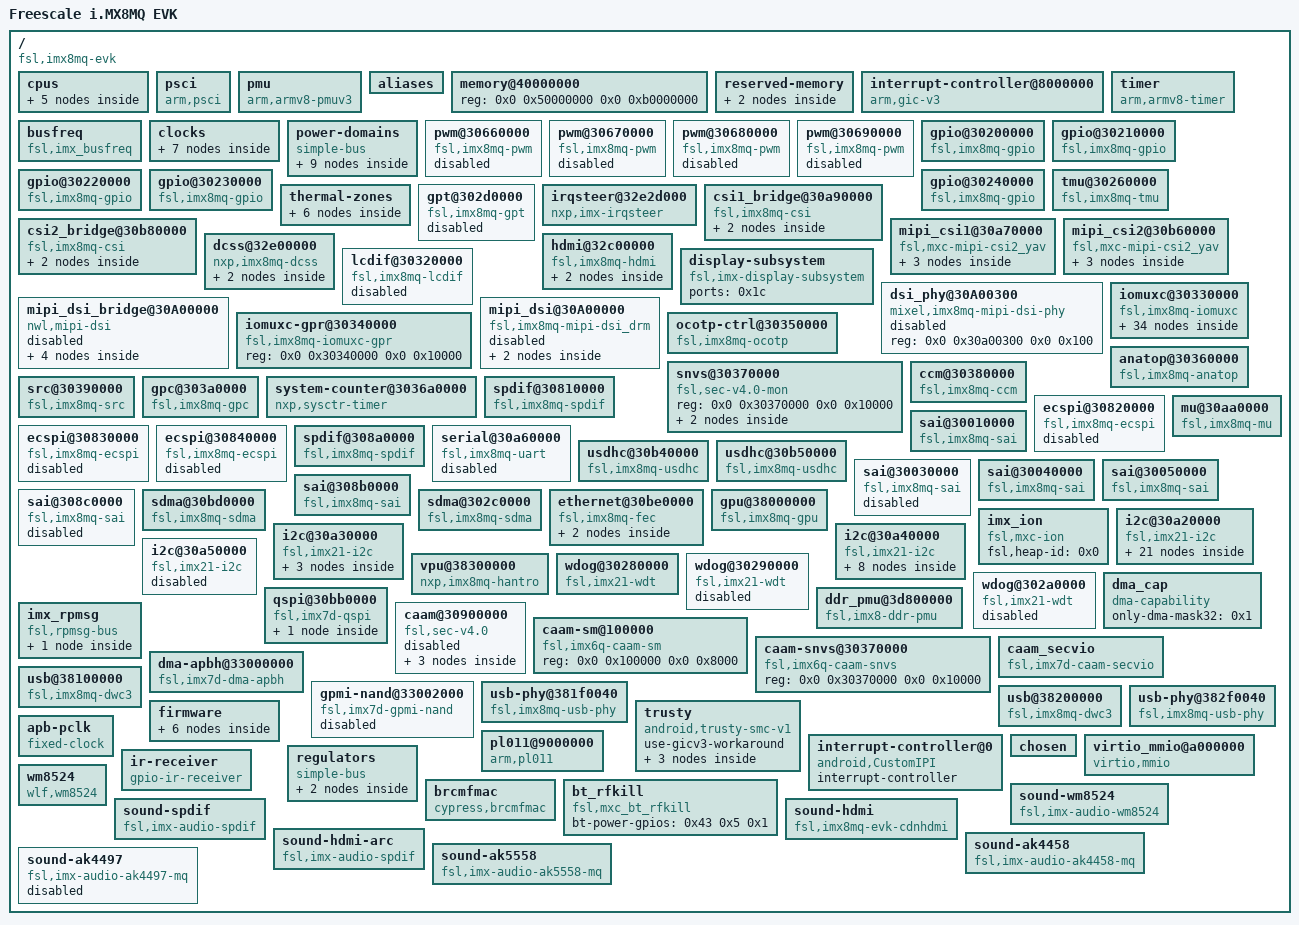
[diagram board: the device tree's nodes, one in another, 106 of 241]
/dts-v1/;

/ {
	compatible = "fsl,imx8mq-evk", "fsl,imx8mq";
	interrupt-parent = <0x1>;
	#address-cells = <0x2>;
	#size-cells = <0x2>;
	model = "Freescale i.MX8MQ EVK";

	cpus {
		#address-cells = <0x2>;
		#size-cells = <0x0>;

		idle-states {
			entry-method = "psci";

			cpu-sleep {
				compatible = "arm,idle-state";
				arm,psci-suspend-param = <0x10033>;
				entry-latency-us = <0x3e8>;
				exit-latency-us = <0x2bc>;
				min-residency-us = <0xa8c>;
				local-timer-stop;
				wakeup-latency-us = <0x5dc>;
				phandle = <0x3>;
			};

			cluster-sleep {
				compatible = "arm,idle-state";
				arm,psci-suspend-param = <0x1000000>;
				entry-latency-us = <0x3e8>;
				exit-latency-us = <0x2bc>;
				min-residency-us = <0xa8c>;
				wakeup-latency-us = <0x5dc>;
			};
		};

		cpu@0 {
			device_type = "cpu";
			compatible = "arm,cortex-a53";
			reg = <0x0 0x0>;
			enable-method = "psci";
			next-level-cache = <0x2>;
			cpu-idle-states = <0x3>;
			operating-points = <0x16e360 0xf4240 0x13d620 0xf4240 0xf4240 0xdbba0 0xc3500 0xdbba0>;
			clocks = <0x4 0x5a 0x4 0x58 0x4 0xa 0x4 0xc 0x4 0x4e>;
			clock-names = "a53", "arm_a53_src", "arm_pll", "arm_pll_out", "sys1_pll_800m";
			clock-latency = <0xee6c>;
			#cooling-cells = <0x2>;
			dc-supply = <0x5>;
			phandle = <0x6>;
		};
/*
		cpu@1 {
			device_type = "cpu";
			compatible = "arm,cortex-a53";
			reg = <0x0 0x1>;
			enable-method = "psci";
			next-level-cache = <0x2>;
			cpu-idle-states = <0x3>;
			phandle = <0x7>;
		};

		cpu@2 {
			device_type = "cpu";
			compatible = "arm,cortex-a53";
			reg = <0x0 0x2>;
			enable-method = "psci";
			next-level-cache = <0x2>;
			cpu-idle-states = <0x3>;
			phandle = <0x8>;
		};

		cpu@3 {
			device_type = "cpu";
			compatible = "arm,cortex-a53";
			reg = <0x0 0x3>;
			enable-method = "psci";
			next-level-cache = <0x2>;
			cpu-idle-states = <0x3>;
			phandle = <0x9>;
		};
*/
		l2-cache0 {
			compatible = "cache";
			phandle = <0x2>;
		};
	};

	psci {
		compatible = "arm,psci";
		method = "hvc";
		cpu_suspend = <0xc4000001>;
		cpu_off = <0xc4000002>;
		cpu_on = <0xc4000003>;
	};

	pmu {
		compatible = "arm,armv8-pmuv3";
		interrupts = <0x1 0x7 0x3f04>;
		interrupt-affinity = <0x6 0x7 0x8 0x9>;
		interrupt-parent = <0xa>;
	};

	aliases {
		csi0 = "/mipi_csi1@30a70000";
		csi1 = "/mipi_csi2@30b60000";
		ethernet0 = "/ethernet@30be0000";
		serial0 = "/serial@30860000";
		serial1 = "/serial@30890000";
		serial2 = "/serial@30880000";
		serial3 = "/serial@30a60000";
		spi0 = "/ecspi@30820000";
		spi1 = "/ecspi@30830000";
		spi2 = "/ecspi@30840000";
		mmc0 = "/usdhc@30b40000";
		mmc1 = "/usdhc@30b50000";
		gpio0 = "/gpio@30200000";
		gpio1 = "/gpio@30210000";
		gpio2 = "/gpio@30220000";
		gpio3 = "/gpio@30230000";
		gpio4 = "/gpio@30240000";
		dsi_phy0 = "/dsi_phy@30A00300";
		mipi_dsi0 = "/mipi_dsi@30A00000";
	};

	memory@40000000 {
		device_type = "memory";
		reg = <0x0 0x50000000 0x0 0xb0000000>;
	};

	reserved-memory {
		#address-cells = <0x2>;
		#size-cells = <0x2>;
		ranges;

		rpmsg@b8000000 {
			no-map;
			reg = <0x0 0xb8000000 0x0 0x400000>;
			phandle = <0x52>;
		};

		imx_ion@0 {
			compatible = "imx-ion-pool";
			/* reg = <0x0 0xf6000000 0x0 0x8000000>; */
			reg = <0x0 0x96400000 0x0 0x2000000>;
		};
	};

	interrupt-controller@8000000 {
		compatible = "arm,gic-v3";
		phandle = <0xa>;
		interrupts = <0x1 0x9 0x4>;
		interrupt-parent = <0xa>;
		reg = <0x00 0x8000000 0x00 0x10000 0x00 0x80a0000 0x00 0xf60000>;
		ranges;
		#address-cells = <0x02>;
		#redistributor-regions = <0x01>;
		interrupt-controller;
		#interrupt-cells = <0x03>;
		#size-cells = <0x02>;
	};

	timer {
		interrupts = <0x01 0x0d 0x04 0x01 0x0e 0x04 0x01 0x0b 0x04 0x01 0x0a 0x04>;
		compatible = "arm,armv8-timer\0arm,armv7-timer";
		always-on;
		interrupt-parent = <0xa>;
	};

	busfreq {
		compatible = "fsl,imx_busfreq";
		clocks = <0x4 0xf8 0x4 0x75 0x4 0x76 0x4 0x76 0x4 0x112 0x4 0x111 0x4 0x46 0x4 0x4d 0x4 0x48 0x4 0x4e 0x4 0x71 0x4 0x67 0x4 0x73 0x4 0x2 0x4 0x55 0x4 0x49>;
		clock-names = "dram_pll", "dram_alt_src", "dram_apb_src", "dram_apb_pre_div", "dram_core", "dram_alt_root", "sys1_pll_40m", "sys1_pll_400m", "sys1_pll_100m", "sys1_pll_800m", "noc_div", "main_axi_src", "ahb_div", "osc_25m", "sys2_pll_333m", "sys1_pll_133m";
		interrupts = <0x0 0x66 0x4 0x0 0x6d 0x4 0x0 0x6e 0x4 0x0 0x6f 0x4>;
		interrupt-name = "irq_busfreq_0", "irq_busfreq_1", "irq_busfreq_2", "irq_busfreq_3";
	};

	clocks {
		#address-cells = <0x1>;
		#size-cells = <0x0>;

		clock@0 {
			compatible = "fixed-clock";
			reg = <0x0>;
			#clock-cells = <0x0>;
			clock-frequency = <0x8000>;
			clock-output-names = "ckil";
			phandle = <0x24>;
		};

		clock@1 {
			compatible = "fixed-clock";
			reg = <0x1>;
			#clock-cells = <0x0>;
			clock-frequency = <0x17d7840>;
			clock-output-names = "osc_25m";
			phandle = <0x25>;
		};

		clock@2 {
			compatible = "fixed-clock";
			reg = <0x2>;
			#clock-cells = <0x0>;
			clock-frequency = <0x19bfcc0>;
			clock-output-names = "osc_27m";
			phandle = <0x26>;
		};

		clock@3 {
			compatible = "fixed-clock";
			reg = <0x3>;
			#clock-cells = <0x0>;
			clock-frequency = <0x7ed6b40>;
			clock-output-names = "clk_ext1";
			phandle = <0x27>;
		};

		clock@4 {
			compatible = "fixed-clock";
			reg = <0x4>;
			#clock-cells = <0x0>;
			clock-frequency = <0x7ed6b40>;
			clock-output-names = "clk_ext2";
			phandle = <0x28>;
		};

		clock@5 {
			compatible = "fixed-clock";
			reg = <0x5>;
			#clock-cells = <0x0>;
			clock-frequency = <0x7ed6b40>;
			clock-output-names = "clk_ext3";
			phandle = <0x29>;
		};

		clock@6 {
			compatible = "fixed-clock";
			reg = <0x6>;
			#clock-cells = <0x0>;
			clock-frequency = <0x7ed6b40>;
			clock-output-names = "clk_ext4";
			phandle = <0x2a>;
		};
	};

	power-domains {
		compatible = "simple-bus";
		#address-cells = <0x1>;
		#size-cells = <0x0>;

		power-domain@0 {
			compatible = "fsl,imx8mq-pm-domain";
			reg = <0x0>;
			#power-domain-cells = <0x0>;
			domain-name = "MIPI_PD";
			phandle = <0x20>;
		};

		power-domain@1 {
			compatible = "fsl,imx8mq-pm-domain";
			reg = <0x1>;
			#power-domain-cells = <0x0>;
			domain-name = "PCIE0_PD";
			phandle = <0x53>;
		};

		power-domain@2 {
			compatible = "fsl,imx8mq-pm-domain";
			reg = <0x2>;
			#power-domain-cells = <0x0>;
			domain-name = "USB_OTG1_PD";
			phandle = <0x59>;
		};

		power-domain@3 {
			compatible = "fsl,imx8mq-pm-domain";
			reg = <0x3>;
			#power-domain-cells = <0x0>;
			domain-name = "USB_OTG2_PD";
			phandle = <0x5c>;
		};

		power-domain@4 {
			compatible = "fsl,imx8mq-pm-domain";
			reg = <0x4>;
			#power-domain-cells = <0x0>;
			domain-name = "GPU_PD";
			clocks = <0x4 0x6f 0x4 0x66 0x4 0xe5 0x4 0x70>;
			power-supply = <0xb>;
			phandle = <0x40>;
		};

		power-domain@5 {
			compatible = "fsl,imx8mq-pm-domain";
			reg = <0x5>;
			#power-domain-cells = <0x0>;
			domain-name = "VPU_PD";
			clocks = <0x4 0xf3 0x4 0xf4 0x4 0xed>;
			power-supply = <0xc>;
			phandle = <0x4f>;
		};

		power-domain@8 {
			compatible = "fsl,imx8mq-pm-domain";
			reg = <0x8>;
			#power-domain-cells = <0x0>;
			domain-name = "MIPI_CSI1_PD";
			phandle = <0x11>;
		};

		power-domain@9 {
			compatible = "fsl,imx8mq-pm-domain";
			reg = <0x9>;
			#power-domain-cells = <0x0>;
			domain-name = "MIPI_CSI2_PD";
			phandle = <0x16>;
		};

		power-domain@10 {
			compatible = "fsl,imx8mq-pm-domain";
			reg = <0xa>;
			#power-domain-cells = <0x0>;
			domain-name = "PCIE1_PD";
			phandle = <0x55>;
		};
	};

	pwm@30660000 {
		compatible = "fsl,imx8mq-pwm", "fsl,imx27-pwm";
		reg = <0x0 0x30660000 0x0 0x10000>;
		interrupts = <0x0 0x51 0x4>;
		clocks = <0x4 0xcd 0x4 0xcd>;
		clock-names = "ipg", "per";
		#pwm-cells = <0x2>;
		status = "disabled";
	};

	pwm@30670000 {
		compatible = "fsl,imx8mq-pwm", "fsl,imx27-pwm";
		reg = <0x0 0x30670000 0x0 0x10000>;
		interrupts = <0x0 0x52 0x4>;
		clocks = <0x4 0xce 0x4 0xce>;
		clock-names = "ipg", "per";
		#pwm-cells = <0x2>;
		status = "disabled";
	};

	pwm@30680000 {
		compatible = "fsl,imx8mq-pwm", "fsl,imx27-pwm";
		reg = <0x0 0x30680000 0x0 0x10000>;
		interrupts = <0x0 0x53 0x4>;
		clocks = <0x4 0xcf 0x4 0xcf>;
		clock-names = "ipg", "per";
		#pwm-cells = <0x2>;
		status = "disabled";
	};

	pwm@30690000 {
		compatible = "fsl,imx8mq-pwm", "fsl,imx27-pwm";
		reg = <0x0 0x30690000 0x0 0x10000>;
		interrupts = <0x0 0x54 0x4>;
		clocks = <0x4 0xd0 0x4 0xd0>;
		clock-names = "ipg", "per";
		#pwm-cells = <0x2>;
		status = "disabled";
	};

	gpio@30200000 {
		compatible = "fsl,imx8mq-gpio", "fsl,imx35-gpio";
		reg = <0x0 0x30200000 0x0 0x10000>;
		interrupts = <0x0 0x40 0x4 0x0 0x41 0x4>;
		gpio-controller;
		#gpio-cells = <0x2>;
		interrupt-controller;
		#interrupt-cells = <0x2>;
		phandle = <0x46>;
	};

	gpio@30210000 {
		compatible = "fsl,imx8mq-gpio", "fsl,imx35-gpio";
		reg = <0x0 0x30210000 0x0 0x10000>;
		interrupts = <0x0 0x42 0x4 0x0 0x43 0x4>;
		gpio-controller;
		#gpio-cells = <0x2>;
		interrupt-controller;
		#interrupt-cells = <0x2>;
		phandle = <0x36>;
	};

	gpio@30220000 {
		compatible = "fsl,imx8mq-gpio", "fsl,imx35-gpio";
		reg = <0x0 0x30220000 0x0 0x10000>;
		interrupts = <0x0 0x44 0x4 0x0 0x45 0x4>;
		gpio-controller;
		#gpio-cells = <0x2>;
		interrupt-controller;
		#interrupt-cells = <0x2>;
		phandle = <0x43>;
	};

	gpio@30230000 {
		compatible = "fsl,imx8mq-gpio", "fsl,imx35-gpio";
		reg = <0x0 0x30230000 0x0 0x10000>;
		interrupts = <0x0 0x46 0x4 0x0 0x47 0x4>;
		gpio-controller;
		#gpio-cells = <0x2>;
		interrupt-controller;
		#interrupt-cells = <0x2>;
	};

	gpio@30240000 {
		compatible = "fsl,imx8mq-gpio", "fsl,imx35-gpio";
		reg = <0x0 0x30240000 0x0 0x10000>;
		interrupts = <0x0 0x48 0x4 0x0 0x49 0x4>;
		gpio-controller;
		#gpio-cells = <0x2>;
		interrupt-controller;
		#interrupt-cells = <0x2>;
		phandle = <0x4d>;
	};

	tmu@30260000 {
		compatible = "fsl,imx8mq-tmu";
		reg = <0x0 0x30260000 0x0 0x10000>;
		interrupt = <0x0 0x31 0x4>;
		little-endian;
		fsl,tmu-range = <0xb0000 0xa0026 0x80048 0x70061>;
		fsl,tmu-calibration = <0x0 0x23 0x1 0x29 0x2 0x2f 0x3 0x35 0x4 0x3d 0x5 0x43 0x6 0x4b 0x7 0x51 0x8 0x57 0x9 0x5f 0xa 0x67 0xb 0x6f 0x10000 0x1b 0x10001 0x23 0x10002 0x2b 0x10003 0x33 0x10004 0x3b 0x10005 0x43 0x10006 0x4b 0x10007 0x55 0x10008 0x5d 0x10009 0x67 0x1000a 0x70 0x20000 0x17 0x20001 0x23 0x20002 0x2d 0x20003 0x37 0x20004 0x41 0x20005 0x4b 0x20006 0x57 0x20007 0x63 0x20008 0x6f 0x30000 0x15 0x30001 0x21 0x30002 0x2d 0x30003 0x39 0x30004 0x45 0x30005 0x53 0x30006 0x5f 0x30007 0x71>;
		#thermal-sensor-cells = <0x0>;
		phandle = <0xd>;
	};

	thermal-zones {

		cpu-thermal {
			polling-delay-passive = <0xfa>;
			polling-delay = <0x7d0>;
			thermal-sensors = <0xd>;

			trips {

				trip0 {
					temperature = <0x14c08>;
					hysteresis = <0x7d0>;
					type = "passive";
					phandle = <0xe>;
				};

				trip1 {
					temperature = <0x17318>;
					hysteresis = <0x7d0>;
					type = "critical";
				};
			};

			cooling-maps {

				map0 {
					trip = <0xe>;
					cooling-device = <0x6 0xffffffff 0xffffffff>;
				};
			};
		};
	};

	gpt@302d0000 {
		compatible = "fsl,imx8mq-gpt", "fsl,imx7d-gpt";
		reg = <0x0 0x302d0000 0x0 0x10000>;
		interrupts = <0x0 0x37 0x4>;
		clocks = <0x4 0xc5 0x4 0xc5 0x4 0xf9>;
		clock-names = "ipg", "per", "osc_per";
		status = "disabled";
	};

	irqsteer@32e2d000 {
		compatible = "nxp,imx-irqsteer";
		reg = <0x0 0x32e2d000 0x0 0x1000>;
		interrupts = <0x0 0x12 0x4>;
		interrupt-controller;
		#interrupt-cells = <0x2>;
		nxp,irqsteer_chans = <0x2>;
		nxp,endian = <0x1>;
		clocks = <0x4 0x10e>;
		clock-names = "ipg";
		phandle = <0x19>;
	};

	csi1_bridge@30a90000 {
		compatible = "fsl,imx8mq-csi", "fsl,imx6s-csi";
		reg = <0x0 0x30a90000 0x0 0x10000>;
		interrupts = <0x0 0x2a 0x4>;
		clocks = <0x4 0x0 0x4 0xee 0x4 0x0>;
		clock-names = "disp-axi", "csi_mclk", "disp_dcic";
		status = "okay";
		fsl,mipi-mode;
		fsl,two-8bit-sensor-mode;

		port {

			endpoint {
				remote-endpoint = <0xf>;
				phandle = <0x15>;
			};
		};
	};

	csi2_bridge@30b80000 {
		compatible = "fsl,imx8mq-csi", "fsl,imx6s-csi";
		reg = <0x0 0x30b80000 0x0 0x10000>;
		interrupts = <0x0 0x2b 0x4>;
		clocks = <0x4 0x0 0x4 0xef 0x4 0x0>;
		clock-names = "disp-axi", "csi_mclk", "disp_dcic";
		status = "okay";
		fsl,mipi-mode;
		fsl,two-8bit-sensor-mode;

		port {

			endpoint {
				remote-endpoint = <0x10>;
				phandle = <0x18>;
			};
		};
	};

	mipi_csi1@30a70000 {
		compatible = "fsl,mxc-mipi-csi2_yav";
		reg = <0x0 0x30a70000 0x0 0x1000>;
		interrupts = <0x0 0x2c 0x4>;
		clocks = <0x4 0x0 0x4 0xa7 0x4 0xa9 0x4 0xa8>;
		clock-names = "clk_apb", "clk_core", "clk_esc", "clk_pxl";
		assigned-clocks = <0x4 0xa7 0x4 0xa8 0x4 0xa9>;
		assigned-clock-rates = <0x7ed6b40 0x5f5e100 0x3ef1480>;
		power-domains = <0x11>;
		csis-phy-reset = <0x12 0x4c 0x7>;
		phy-gpr = <0x13 0x88>;
		status = "okay";
		#address-cells = <0x1>;
		#size-cells = <0x0>;

		port {

			endpoint@0 {
				remote-endpoint = <0x14>;
				data-lanes = <0x1 0x2>;
				phandle = <0x4a>;
			};

			endpoint@1 {
				remote-endpoint = <0x15>;
				phandle = <0xf>;
			};
		};
	};

	mipi_csi2@30b60000 {
		compatible = "fsl,mxc-mipi-csi2_yav";
		reg = <0x0 0x30b60000 0x0 0x1000>;
		interrupts = <0x0 0x2d 0x4>;
		clocks = <0x4 0x0 0x4 0xaa 0x4 0xac 0x4 0xab>;
		clock-names = "clk_apb", "clk_core", "clk_esc", "clk_pxl";
		assigned-clocks = <0x4 0xaa 0x4 0xab 0x4 0xac>;
		assigned-clock-rates = <0x7ed6b40 0x5f5e100 0x3ef1480>;
		power-domains = <0x16>;
		csis-phy-reset = <0x12 0x50 0x7>;
		phy-gpr = <0x13 0xa4>;
		status = "okay";
		#address-cells = <0x1>;
		#size-cells = <0x0>;

		port {

			endpoint@0 {
				remote-endpoint = <0x17>;
				data-lanes = <0x1 0x2>;
				phandle = <0x47>;
			};

			endpoint@1 {
				remote-endpoint = <0x18>;
				phandle = <0x10>;
			};
		};
	};

	dcss@32e00000 {
		#address-cells = <0x1>;
		#size-cells = <0x0>;
		compatible = "nxp,imx8mq-dcss";
		reg = <0x0 0x32e00000 0x0 0x30000>;
		interrupts = <0x3 0x4 0x4 0x4 0x5 0x4 0x6 0x4 0x8 0x4 0x9 0x1 0x10 0x4 0x11 0x4>;
		interrupt-names = "dpr_dc_ch0", "dpr_dc_ch1", "dpr_dc_ch2", "ctx_ld", "ctxld_kick", "dtg_prg1", "dtrc_ch1", "dtrc_ch2";
		interrupt-parent = <0x19>;
		clocks = <0x4 0x10e 0x4 0x10d 0x4 0x10f 0x4 0x114 0x4 0x79 0x4 0x104 0x4 0x117>;
		clock-names = "apb", "axi", "rtrm", "pix", "dtrc", "pll_src", "pll_phy_ref";
		assigned-clocks = <0x4 0x7e 0x4 0x6b 0x4 0x6d 0x4 0x104>;
		assigned-clock-parents = <0x4 0x25 0x4 0x4e 0x4 0x4e 0x4 0x3>;
		assigned-clock-rates = <0x2367b880 0x2faf0800 0x17d78400>;
		status = "okay";
		disp-dev = "hdmi_disp";

		port@0 {
			reg = <0x0>;
			phandle = <0x1c>;

			endpoint {
				remote-endpoint = <0x1a>;
				phandle = <0x1b>;
			};
		};
	};

	hdmi@32c00000 {
		#address-cells = <0x1>;
		#size-cells = <0x0>;
		compatible = "fsl,imx8mq-hdmi";
		reg = <0x0 0x32c00000 0x0 0x100000 0x0 0x32e40000 0x0 0x40000 0x0 0x32e2f000 0x0 0x10>;
		interrupts = <0x0 0x10 0x4 0x0 0x19 0x4>;
		interrupt-names = "plug_in", "plug_out";
		fsl,cec;
		status = "okay";

		port@0 {
			reg = <0x0>;

			endpoint {
				remote-endpoint = <0x1b>;
				phandle = <0x1a>;
			};
		};
	};

	lcdif@30320000 {
		compatible = "fsl,imx8mq-lcdif", "fsl,imx28-lcdif";
		reg = <0x0 0x30320000 0x0 0x10000>;
		clocks = <0x4 0x7f>;
		clock-names = "pix";
		assigned-clocks = <0x4 0x7f>;
		assigned-clock-parents = <0x4 0x25>;
		assigned-clock-rate = <0x2367b880>;
		interrupts = <0x0 0x5 0x4>;
		status = "disabled";
	};

	display-subsystem {
		compatible = "fsl,imx-display-subsystem";
		ports = <0x1c>;
	};

	dsi_phy@30A00300 {
		#address-cells = <0x1>;
		#size-cells = <0x0>;
		compatible = "mixel,imx8mq-mipi-dsi-phy";
		reg = <0x0 0x30a00300 0x0 0x100>;
		#phy-cells = <0x0>;
		status = "disabled";
		phandle = <0x1d>;
	};

	mipi_dsi_bridge@30A00000 {
		#address-cells = <0x1>;
		#size-cells = <0x0>;
		compatible = "nwl,mipi-dsi";
		reg = <0x0 0x30a00000 0x0 0x400>;
		interrupts = <0x0 0x22 0x4>;
		clocks = <0x4 0xa4 0x4 0x102 0x4 0x103 0x4 0x23>;
		clock-names = "phy_ref", "rx_esc", "tx_esc", "video_pll";
		assigned-clocks = <0x4 0x102>;
		assigned-clock-parents = <0x4 0x47>;
		assigned-clock-rates = <0x4c4b400>;
		phys = <0x1d>;
		phy-names = "dphy";
		no_clk_reset;
		status = "disabled";

		port@0 {

			endpoint {
				remote-endpoint = <0x1e>;
				phandle = <0x21>;
			};
		};

		port@1 {

			endpoint {
				remote-endpoint = <0x1f>;
				phandle = <0x4e>;
			};
		};
	};

	mipi_dsi@30A00000 {
		compatible = "fsl,imx8mq-mipi-dsi_drm";
		clocks = <0x4 0xa3 0x4 0xa4>;
		clock-names = "core", "phy_ref";
		assigned-clocks = <0x4 0xa4 0x4 0xa3>;
		assigned-clock-parents = <0x4 0x25 0x4 0x4c>;
		assigned-clock-rates = <0x2367b880 0xfdad680>;
		power-domains = <0x20>;
		src = <0x12>;
		mux-sel = <0x13>;
		phys = <0x1d>;
		phy-names = "dphy";
		no_clk_reset;
		status = "disabled";

		port@0 {

			endpoint {
				remote-endpoint = <0x21>;
				phandle = <0x1e>;
			};
		};
	};

	iomuxc@30330000 {
		compatible = "fsl,imx8mq-iomuxc";
		reg = <0x0 0x30330000 0x0 0x10000>;
		pinctrl-names = "default";
		pinctrl-0 = <0x22>;

		imx8mq-evk {

			hoggrp {
				fsl,pins = <0x134 0x39c 0x0 0x5 0x0 0x19 0x138 0x3a0 0x0 0x5 0x0 0x19 0x13c 0x3a4 0x0 0x5 0x0 0x19>;
				phandle = <0x22>;
			};

			ir_recv {
				fsl,pins = <0x58 0x2c0 0x0 0x0 0x0 0x4f>;
				phandle = <0x5f>;
			};

			csi1_pwn_grp {
				fsl,pins = <0x34 0x29c 0x0 0x0 0x0 0x19>;
				phandle = <0x49>;
			};

			csi2_pwn_grp {
				fsl,pins = <0x3c 0x2a4 0x0 0x0 0x0 0x19>;
				phandle = <0x44>;
			};

			csi_rst_grp {
				fsl,pins = <0x40 0x2a8 0x0 0x0 0x0 0x19 0x64 0x2cc 0x0 0x6 0x0 0x59>;
				phandle = <0x45>;
			};

			fec1grp {
				fsl,pins = <0x68 0x2d0 0x0 0x0 0x0 0x3 0x6c 0x2d4 0x4c0 0x0 0x1 0x23 0x70 0x2d8 0x0 0x0 0x0 0x1f 0x74 0x2dc 0x0 0x0 0x0 0x1f 0x78 0x2e0 0x0 0x0 0x0 0x1f 0x7c 0x2e4 0x0 0x0 0x0 0x1f 0x9c 0x304 0x0 0x0 0x0 0x91 0x98 0x300 0x0 0x0 0x0 0x91 0x94 0x2fc 0x0 0x0 0x0 0x91 0x90 0x2f8 0x0 0x0 0x0 0x91 0x84 0x2ec 0x0 0x0 0x0 0x1f 0x8c 0x2f4 0x0 0x0 0x0 0x91 0x88 0x2f0 0x0 0x0 0x0 0x91 0x80 0x2e8 0x0 0x0 0x0 0x1f 0x4c 0x2b4 0x0 0x0 0x0 0x19>;
				phandle = <0x3e>;
			};

			i2c1grp {
				fsl,pins = <0x214 0x47c 0x0 0x0 0x0 0x4000007f 0x218 0x480 0x0 0x0 0x0 0x4000007f>;
				phandle = <0x41>;
			};

			i2c2grp {
				fsl,pins = <0x21c 0x484 0x0 0x0 0x0 0x40000067 0x220 0x488 0x0 0x0 0x0 0x40000067>;
				phandle = <0x48>;
			};

			i2c3grp {
				fsl,pins = <0x224 0x48c 0x0 0x0 0x0 0x40000067 0x228 0x490 0x0 0x0 0x0 0x40000067>;
				phandle = <0x4b>;
			};

			pcie0grp {
				fsl,pins = <0x22c 0x494 0x524 0x12 0x0 0x76 0x250 0x4b8 0x0 0x5 0x0 0x16 0x24c 0x4b4 0x0 0x5 0x0 0x16>;
				phandle = <0x54>;
			};

			pcie1grp {
				fsl,pins = <0x230 0x498 0x528 0x12 0x0 0x76 0x204 0x46c 0x0 0x5 0x0 0x16 0x20c 0x474 0x0 0x5 0x0 0x16>;
				phandle = <0x56>;
			};

			dvfsgrp {
				fsl,pins = <0x5c 0x2c4 0x0 0x0 0x0 0x16>;
				phandle = <0x5e>;
			};

			typecgrp {
				fsl,pins = <0x130 0x398 0x0 0x5 0x0 0x16 0x100 0x368 0x0 0x5 0x0 0x17059>;
				phandle = <0x42>;
			};

			qspigrp {
				fsl,pins = <0xf4 0x35c 0x0 0x1 0x0 0x82 0xf8 0x360 0x0 0x1 0x0 0x82 0x10c 0x374 0x0 0x1 0x0 0x82 0x110 0x378 0x0 0x1 0x0 0x82 0x114 0x37c 0x0 0x1 0x0 0x82 0x118 0x380 0x0 0x1 0x0 0x82>;
				phandle = <0x51>;
			};

			uart1grp {
				fsl,pins = <0x234 0x49c 0x4f4 0x0 0x0 0x49 0x238 0x4a0 0x0 0x0 0x0 0x49>;
				phandle = <0x2d>;
			};

			uart3grp {
				fsl,pins = <0x248 0x4b0 0x0 0x0 0x0 0x49 0x244 0x4ac 0x504 0x0 0x2 0x49 0x1fc 0x464 0x0 0x1 0x0 0x49 0x200 0x468 0x500 0x1 0x1 0x49 0x108 0x370 0x0 0x5 0x0 0x19>;
				phandle = <0x2e>;
			};

			usdhc1grp {
				fsl,pins = <0xa0 0x308 0x0 0x0 0x0 0x83 0xa4 0x30c 0x0 0x0 0x0 0xc3 0xa8 0x310 0x0 0x0 0x0 0xc3 0xac 0x314 0x0 0x0 0x0 0xc3 0xb0 0x318 0x0 0x0 0x0 0xc3 0xb4 0x31c 0x0 0x0 0x0 0xc3 0xb8 0x320 0x0 0x0 0x0 0xc3 0xbc 0x324 0x0 0x0 0x0 0xc3 0xc0 0x328 0x0 0x0 0x0 0xc3 0xc4 0x32c 0x0 0x0 0x0 0xc3 0xcc 0x334 0x0 0x0 0x0 0x83 0xc8 0x330 0x0 0x0 0x0 0xc1>;
				phandle = <0x2f>;
			};

			usdhc1grp100mhz {
				fsl,pins = <0xa0 0x308 0x0 0x0 0x0 0x8d 0xa4 0x30c 0x0 0x0 0x0 0xcd 0xa8 0x310 0x0 0x0 0x0 0xcd 0xac 0x314 0x0 0x0 0x0 0xcd 0xb0 0x318 0x0 0x0 0x0 0xcd 0xb4 0x31c 0x0 0x0 0x0 0xcd 0xb8 0x320 0x0 0x0 0x0 0xcd 0xbc 0x324 0x0 0x0 0x0 0xcd 0xc0 0x328 0x0 0x0 0x0 0xcd 0xc4 0x32c 0x0 0x0 0x0 0xcd 0xcc 0x334 0x0 0x0 0x0 0x8d 0xc8 0x330 0x0 0x0 0x0 0xc1>;
				phandle = <0x30>;
			};

			usdhc1grp200mhz {
				fsl,pins = <0xa0 0x308 0x0 0x0 0x0 0x9f 0xa4 0x30c 0x0 0x0 0x0 0xdf 0xa8 0x310 0x0 0x0 0x0 0xdf 0xac 0x314 0x0 0x0 0x0 0xdf 0xb0 0x318 0x0 0x0 0x0 0xdf 0xb4 0x31c 0x0 0x0 0x0 0xdf 0xb8 0x320 0x0 0x0 0x0 0xdf 0xbc 0x324 0x0 0x0 0x0 0xdf 0xc0 0x328 0x0 0x0 0x0 0xdf 0xc4 0x32c 0x0 0x0 0x0 0xdf 0xcc 0x334 0x0 0x0 0x0 0x9f 0xc8 0x330 0x0 0x0 0x0 0xc1>;
				phandle = <0x31>;
			};

			usdhc2grpgpio {
				fsl,pins = <0xd0 0x338 0x0 0x5 0x0 0x41 0xec 0x354 0x0 0x5 0x0 0x41>;
				phandle = <0x33>;
			};

			usdhc2grp {
				fsl,pins = <0xd4 0x33c 0x0 0x0 0x0 0x83 0xd8 0x340 0x0 0x0 0x0 0xc3 0xdc 0x344 0x0 0x0 0x0 0xc3 0xe0 0x348 0x0 0x0 0x0 0xc3 0xe4 0x34c 0x0 0x0 0x0 0xc3 0xe8 0x350 0x0 0x0 0x0 0xc3 0x38 0x2a0 0x0 0x1 0x0 0xc1>;
				phandle = <0x32>;
			};

			usdhc2grp100mhz {
				fsl,pins = <0xd4 0x33c 0x0 0x0 0x0 0x8d 0xd8 0x340 0x0 0x0 0x0 0xcd 0xdc 0x344 0x0 0x0 0x0 0xcd 0xe0 0x348 0x0 0x0 0x0 0xcd 0xe4 0x34c 0x0 0x0 0x0 0xcd 0xe8 0x350 0x0 0x0 0x0 0xcd 0x38 0x2a0 0x0 0x1 0x0 0xc1>;
				phandle = <0x34>;
			};

			usdhc2grp200mhz {
				fsl,pins = <0xd4 0x33c 0x0 0x0 0x0 0x9f 0xd8 0x340 0x0 0x0 0x0 0xdf 0xdc 0x344 0x0 0x0 0x0 0xdf 0xe0 0x348 0x0 0x0 0x0 0xdf 0xe4 0x34c 0x0 0x0 0x0 0xdf 0xe8 0x350 0x0 0x0 0x0 0xdf 0x38 0x2a0 0x0 0x1 0x0 0xc1>;
				phandle = <0x35>;
			};

			sai1grp_pcm {
				fsl,pins = <0x1ac 0x414 0x0 0x0 0x0 0xd6 0x184 0x3ec 0x4cc 0x0 0x3 0xd6 0x180 0x3e8 0x4cc 0x2 0x4 0xd6 0x188 0x3f0 0x4c8 0x0 0x1 0xd6 0x18c 0x3f4 0x0 0x0 0x0 0xd6 0x190 0x3f8 0x0 0x0 0x0 0xd6 0x194 0x3fc 0x0 0x0 0x0 0xd6 0x198 0x400 0x0 0x0 0x0 0xd6 0x19c 0x404 0x0 0x0 0x0 0xd6 0x1a0 0x408 0x0 0x0 0x0 0xd6 0x1a4 0x40c 0x0 0x0 0x0 0xd6 0x1a8 0x410 0x0 0x0 0x0 0xd6>;
				phandle = <0x39>;
			};

			sai1grp_pcm_b2m {
				fsl,pins = <0x1ac 0x414 0x4c8 0x2 0x2 0xd6 0x184 0x3ec 0x4cc 0x0 0x3 0xd6 0x180 0x3e8 0x4cc 0x2 0x4 0xd6 0x188 0x3f0 0x4c8 0x0 0x1 0xd6 0x18c 0x3f4 0x0 0x0 0x0 0xd6 0x190 0x3f8 0x0 0x0 0x0 0xd6 0x194 0x3fc 0x0 0x0 0x0 0xd6 0x198 0x400 0x0 0x0 0x0 0xd6 0x19c 0x404 0x0 0x0 0x0 0xd6 0x1a0 0x408 0x0 0x0 0x0 0xd6 0x1a4 0x40c 0x0 0x0 0x0 0xd6 0x1a8 0x410 0x0 0x0 0x0 0xd6>;
				phandle = <0x3a>;
			};

			sai1grp_dsd {
				fsl,pins = <0x1ac 0x414 0x0 0x0 0x0 0xd6 0x184 0x3ec 0x4cc 0x0 0x3 0xd6 0x180 0x3e8 0x0 0x3 0x0 0xd6 0x188 0x3f0 0x4c8 0x0 0x1 0xd6 0x18c 0x3f4 0x0 0x0 0x0 0xd6 0x190 0x3f8 0x0 0x0 0x0 0xd6 0x194 0x3fc 0x0 0x0 0x0 0xd6 0x198 0x400 0x0 0x0 0x0 0xd6 0x19c 0x404 0x0 0x0 0x0 0xd6 0x1a0 0x408 0x0 0x0 0x0 0xd6 0x1a4 0x40c 0x0 0x0 0x0 0xd6 0x1a8 0x410 0x0 0x0 0x0 0xd6>;
				phandle = <0x3b>;
			};

			sai2grp {
				fsl,pins = <0x1bc 0x424 0x0 0x0 0x0 0xd6 0x1c0 0x428 0x0 0x0 0x0 0xd6 0x1c8 0x430 0x0 0x0 0x0 0xd6 0x1c4 0x42c 0x0 0x0 0x0 0xd6 0x48 0x2b0 0x0 0x0 0x0 0xd6>;
				phandle = <0x3d>;
			};

			sai5grp {
				fsl,pins = <0x158 0x3c0 0x52c 0x0 0x0 0xd6 0x144 0x3ac 0x4d0 0x0 0x0 0xd6 0x140 0x3a8 0x4e4 0x0 0x0 0xd6 0x148 0x3b0 0x4d4 0x0 0x0 0xd6 0x14c 0x3b4 0x4d8 0x0 0x0 0xd6 0x150 0x3b8 0x4dc 0x0 0x0 0xd6 0x154 0x3bc 0x4e0 0x0 0x0 0xd6>;
				phandle = <0x3c>;
			};

			spdif1grp {
				fsl,pins = <0x1e8 0x450 0x0 0x0 0x0 0xd6 0x1ec 0x454 0x0 0x0 0x0 0xd6>;
				phandle = <0x2c>;
			};

			wdoggrp {
				fsl,pins = <0x30 0x298 0x0 0x1 0x0 0xc6>;
				phandle = <0x50>;
			};

			wlangrp {
				fsl,pins = <0x28 0x290 0x0 0x5 0x0 0x16>;
				phandle = <0x61>;
			};

			wlan_initgrp {
				fsl,pins = <0x28 0x290 0x0 0x0 0x0 0x16>;
				phandle = <0x60>;
			};

			dsi_ts_int {
				fsl,pins = <0x1f8 0x460 0x0 0x5 0x0 0x19>;
				phandle = <0x4c>;
			};
		};
	};

	iomuxc-gpr@30340000 {
		compatible = "fsl,imx8mq-iomuxc-gpr", "fsl,imx7d-iomuxc-gpr", "syscon";
		reg = <0x0 0x30340000 0x0 0x10000>;
		phandle = <0x13>;
	};

	ocotp-ctrl@30350000 {
		compatible = "fsl,imx8mq-ocotp", "fsl,imx7d-ocotp", "syscon";
		reg = <0x0 0x30350000 0x0 0x10000>;
		clocks = <0x4 0x110>;
		#address-cells = <0x1>;
		#size-cells = <0x1>;
	};

	anatop@30360000 {
		compatible = "fsl,imx8mq-anatop", "fsl,imx6q-anatop", "syscon", "simple-bus";
		reg = <0x0 0x30360000 0x0 0x10000>;
		interrupts = <0x0 0x31 0x4>;
	};

	snvs@30370000 {
		compatible = "fsl,sec-v4.0-mon", "syscon", "simple-mfd";
		reg = <0x0 0x30370000 0x0 0x10000>;
		phandle = <0x23>;

		snvs-rtc-lp {
			compatible = "fsl,sec-v4.0-mon-rtc-lp";
			regmap = <0x23>;
			offset = <0x34>;
			interrupts = <0x0 0x13 0x4 0x0 0x14 0x4>;
		};

		snvs-powerkey {
			compatible = "fsl,sec-v4.0-pwrkey";
			regmap = <0x23>;
			interrupts = <0x0 0x4 0x4>;
			linux,keycode = <0x74>;
			wakeup-source;
		};
	};

	ccm@30380000 {
		compatible = "fsl,imx8mq-ccm";
		reg = <0x0 0x30380000 0x0 0x10000>;
		interrupts = <0x0 0x55 0x4 0x0 0x56 0x4>;
		#clock-cells = <0x1>;
		clocks = <0x24 0x25 0x26 0x27 0x28 0x29 0x2a>;
		clock-names = "ckil", "osc_25m", "osc_27m", "clk_ext1", "clk_ext2", "clk_ext3", "clk_ext4";
		assigned-clocks = <0x4 0x19 0x4 0x1e>;
		assigned-clock-rates = <0x2ee00000 0x2b110000>;
		phandle = <0x4>;
	};

	src@30390000 {
		compatible = "fsl,imx8mq-src", "fsl,imx51-src", "syscon";
		reg = <0x0 0x30390000 0x0 0x10000>;
		interrupts = <0x0 0x59 0x4>;
		#reset-cells = <0x1>;
		phandle = <0x12>;
	};

	gpc@303a0000 {
		compatible = "fsl,imx8mq-gpc", "fsl,imx7d-gpc", "syscon";
		reg = <0x0 0x303a0000 0x0 0x10000>;
		interrupt-controller;
		interrupts = <0x0 0x57 0x4>;
		#interrupt-cells = <0x3>;
		interrupt-parent = <0xa>;
		phandle = <0x1>;
	};

	system-counter@3036a0000 {
		compatible = "nxp,sysctr-timer";
		reg = <0x0 0x306a0000 0x0 0x10000 0x0 0x306b0000 0x0 0x10000 0x0 0x306c0000 0x0 0x10000>;
		clock-frequency = <0x7f2815>;
		interrupts = <0x0 0x2f 0x4 0x0 0x30 0x4>;
	};

	spdif@30810000 {
		compatible = "fsl,imx8mq-spdif", "fsl,imx35-spdif";
		reg = <0x0 0x30810000 0x0 0x10000>;
		interrupts = <0x0 0x6 0x4>;
		clocks = <0x4 0xfa 0x4 0x2 0x4 0x86 0x4 0x0 0x4 0x0 0x4 0x0 0x4 0xfa 0x4 0x0 0x4 0x0 0x4 0x0 0x4 0x1b 0x4 0x20>;
		clock-names = "core", "rxtx0", "rxtx1", "rxtx2", "rxtx3", "rxtx4", "rxtx5", "rxtx6", "rxtx7", "spba", "pll8k", "pll11k";
		dmas = <0x2b 0x8 0x12 0x0 0x2b 0x9 0x12 0x0>;
		dma-names = "rx", "tx";
		status = "okay";
		pinctrl-names = "default";
		pinctrl-0 = <0x2c>;
		assigned-clocks = <0x4 0x86>;
		assigned-clock-parents = <0x4 0x1b>;
		assigned-clock-rates = <0x1770000>;
		phandle = <0x65>;
	};

	ecspi@30820000 {
		compatible = "fsl,imx8mq-ecspi", "fsl,imx51-ecspi";
		reg = <0x0 0x30820000 0x0 0x10000>;
		interrupts = <0x0 0x1f 0x4>;
		clocks = <0x4 0xc1 0x4 0xc1>;
		clock-names = "ipg", "per";
		status = "disabled";
		#address-cells = <0x1>;
		#size-cells = <0x0>;
	};

	ecspi@30830000 {
		#address-cells = <0x1>;
		#size-cells = <0x0>;
		compatible = "fsl,imx8mq-ecspi", "fsl,imx51-ecspi";
		reg = <0x0 0x30830000 0x0 0x10000>;
		interrupts = <0x0 0x20 0x4>;
		clocks = <0x4 0xc2 0x4 0xc2>;
		clock-names = "ipg", "per";
		status = "disabled";
	};

	ecspi@30840000 {
		#address-cells = <0x1>;
		#size-cells = <0x0>;
		compatible = "fsl,imx8mq-ecspi", "fsl,imx51-ecspi";
		reg = <0x0 0x30840000 0x0 0x10000>;
		interrupts = <0x0 0x21 0x4>;
		clocks = <0x4 0xc3 0x4 0xc3>;
		clock-names = "ipg", "per";
		status = "disabled";
	};

/*
	serial@30860000 {
		compatible = "fsl,imx8mq-uart", "fsl,imx6q-uart", "fsl,imx21-uart";
		reg = <0x0 0x30860000 0x0 0x10000>;
		interrupts = <0x0 0x1a 0x4>;
		clocks = <0x4 0xd8 0x4 0xd8>;
		clock-names = "ipg", "per";
		status = "okay";
		pinctrl-names = "default";
		pinctrl-0 = <0x2d>;
		assigned-clocks = <0x4 0x94>;
		assigned-clock-parents = <0x4 0x2>;
	};

	serial@30880000 {
		compatible = "fsl,imx8mq-uart", "fsl,imx6q-uart", "fsl,imx21-uart";
		reg = <0x0 0x30880000 0x0 0x10000>;
		interrupts = <0x0 0x1c 0x4>;
		clocks = <0x4 0xda 0x4 0xda>;
		clock-names = "ipg", "per";
		dmas = <0x2b 0x1a 0x4 0x0 0x2b 0x1b 0x4 0x0>;
		dma-names = "rx", "tx";
		status = "okay";
		pinctrl-names = "default";
		pinctrl-0 = <0x2e>;
		assigned-clocks = <0x4 0x96>;
		assigned-clock-parents = <0x4 0x47>;
		fsl,uart-has-rtscts;
	};

	serial@30890000 {
		compatible = "fsl,imx8mq-uart", "fsl,imx6q-uart", "fsl,imx21-uart";
		reg = <0x0 0x30890000 0x0 0x10000>;
		interrupts = <0x0 0x1b 0x4>;
		clocks = <0x4 0xd9 0x4 0xd9>;
		clock-names = "ipg", "per";
		dmas = <0x2b 0x18 0x4 0x0 0x2b 0x19 0x4 0x0>;
		dma-names = "rx", "tx";
		status = "disabled";
	};
*/
	spdif@308a0000 {
		compatible = "fsl,imx8mq-spdif", "fsl,imx35-spdif";
		reg = <0x0 0x308a0000 0x0 0x10000>;
		interrupts = <0x0 0xd 0x4>;
		clocks = <0x4 0xfa 0x4 0x2 0x4 0x87 0x4 0x0 0x4 0x0 0x4 0x0 0x4 0xfa 0x4 0x0 0x4 0x0 0x4 0x0>;
		clock-names = "core", "rxtx0", "rxtx1", "rxtx2", "rxtx3", "rxtx4", "rxtx5", "rxtx6", "rxtx7", "spba";
		dmas = <0x2b 0x10 0x12 0x0 0x2b 0x11 0x12 0x0>;
		dma-names = "rx", "tx";
		status = "okay";
		assigned-clocks = <0x4 0x87>;
		assigned-clock-parents = <0x4 0x1b>;
		assigned-clock-rates = <0x1770000>;
		phandle = <0x66>;
	};

	serial@30a60000 {
		compatible = "fsl,imx8mq-uart", "fsl,imx6q-uart", "fsl,imx21-uart";
		reg = <0x0 0x30a60000 0x0 0x10000>;
		interrupts = <0x0 0x1d 0x4>;
		clocks = <0x4 0xdb 0x4 0xdb>;
		clock-names = "ipg", "per";
		dmas = <0x2b 0x1c 0x4 0x0 0x2b 0x1d 0x4 0x0>;
		dma-names = "rx", "tx";
		status = "disabled";
	};

	mu@30aa0000 {
		compatible = "fsl,imx8mq-mu", "fsl,imx6sx-mu";
		reg = <0x0 0x30aa0000 0x0 0x10000>;
		interrupts = <0x0 0x58 0x4>;
		clocks = <0x4 0x113>;
		clock-names = "mu";
		status = "okay";
	};

	usdhc@30b40000 {
		compatible = "fsl,imx8mq-usdhc", "fsl,imx7d-usdhc";
		reg = <0x0 0x30b40000 0x0 0x10000>;
		interrupts = <0x0 0x16 0x4>;
		clocks = <0x4 0x0 0x4 0x69 0x4 0xe0>;
		clock-names = "ipg", "ahb", "per";
		assigned-clocks = <0x4 0x8d>;
		assigned-clock-rates = <0x17d78400>;
		fsl,tuning-start-tap = <0x14>;
		fsl,tuning-step = <0x2>;
		fsl,strobe-dll-delay-target = <0x5>;
		bus-width = <0x8>;
		status = "okay";
		pinctrl-names = "default", "state_100mhz", "state_200mhz";
		pinctrl-0 = <0x2f>;
		pinctrl-1 = <0x30>;
		pinctrl-2 = <0x31>;
		non-removable;
	};

	usdhc@30b50000 {
		compatible = "fsl,imx8mq-usdhc", "fsl,imx7d-usdhc";
		reg = <0x0 0x30b50000 0x0 0x10000>;
		interrupts = <0x0 0x17 0x4>;
		clocks = <0x4 0x0 0x4 0x69 0x4 0xe1>;
		clock-names = "ipg", "ahb", "per";
		fsl,tuning-start-tap = <0x14>;
		fsl,tuning-step = <0x2>;
		bus-width = <0x4>;
		status = "okay";
		pinctrl-names = "default", "state_100mhz", "state_200mhz";
		pinctrl-0 = <0x32 0x33>;
		pinctrl-1 = <0x34 0x33>;
		pinctrl-2 = <0x35 0x33>;
		cd-gpios = <0x36 0xc 0x1>;
		vmmc-supply = <0x37>;
	};

	sai@30010000 {
		compatible = "fsl,imx8mq-sai", "fsl,imx6sx-sai";
		reg = <0x0 0x30010000 0x0 0x10000>;
		interrupts = <0x0 0x5f 0x4>;
		clocks = <0x4 0xfc 0x4 0x0 0x4 0xd2 0x4 0x0 0x4 0x0 0x4 0x1b 0x4 0x20>;
		clock-names = "bus", "mclk0", "mclk1", "mclk2", "mclk3", "pll8k", "pll11k";
		dmas = <0x38 0x8 0x1a 0x0 0x38 0x9 0x1a 0x0>;
		dma-names = "rx", "tx";
		fsl,dataline = <0x0 0xff 0xff>;
		status = "okay";
		pinctrl-names = "default", "pcm_b2m", "dsd";
		pinctrl-0 = <0x39>;
		pinctrl-1 = <0x3a>;
		pinctrl-2 = <0x3b>;
		assigned-clocks = <0x4 0x80>;
		assigned-clock-parents = <0x4 0x1b>;
		assigned-clock-rates = <0x2ee0000>;
		fsl,sai-multi-lane;
		fsl,dataline,dsd = <0x0 0xff 0xff 0x2 0xff 0x11>;
		phandle = <0x67>;
	};

	sai@30030000 {
		compatible = "fsl,imx8mq-sai", "fsl,imx6sx-sai";
		reg = <0x0 0x30030000 0x0 0x10000>;
		interrupts = <0x0 0x5a 0x4>;
		clocks = <0x4 0x101 0x4 0x0 0x4 0xd7 0x4 0x0 0x4 0x0>;
		clock-names = "bus", "mclk0", "mclk1", "mclk2", "mclk3";
		dmas = <0x38 0x4 0x18 0x0 0x38 0x5 0x18 0x0>;
		dma-names = "rx", "tx";
		fsl,shared-interrupt;
		status = "disabled";
	};

	sai@30040000 {
		compatible = "fsl,imx8mq-sai", "fsl,imx6sx-sai";
		reg = <0x0 0x30040000 0x0 0x10000>;
		interrupts = <0x0 0x5a 0x4>;
		clocks = <0x4 0x100 0x4 0x0 0x4 0xd6 0x4 0x0 0x4 0x0 0x4 0x1b 0x4 0x20>;
		clock-names = "bus", "mclk0", "mclk1", "mclk2", "mclk3", "pll8k", "pll11k";
		dmas = <0x38 0x2 0x18 0x0 0x38 0x3 0x18 0x0>;
		dma-names = "rx", "tx";
		fsl,shared-interrupt;
		fsl,dataline = <0x0 0xf 0xf>;
		status = "okay";
		pinctrl-names = "default";
		pinctrl-0 = <0x3c>;
		assigned-clocks = <0x4 0x84>;
		assigned-clock-parents = <0x4 0x1b>;
		assigned-clock-rates = <0x2ee0000>;
		fsl,sai-asynchronous;
		phandle = <0x6a>;
	};

	sai@30050000 {
		compatible = "fsl,imx8mq-sai", "fsl,imx6sx-sai";
		reg = <0x0 0x30050000 0x0 0x10000>;
		interrupts = <0x0 0x64 0x4>;
		clocks = <0x4 0xff 0x4 0x0 0x4 0xd5 0x4 0x0 0x4 0x0 0x4 0x1b 0x4 0x20>;
		clock-names = "bus", "mclk0", "mclk1", "mclk2", "mclk3", "pll8k", "pll11k";
		dmas = <0x38 0x0 0x18 0x0 0x38 0x1 0x18 0x0>;
		dma-names = "rx", "tx";
		fsl,dataline = <0x0 0x0 0xf>;
		status = "okay";
		assigned-clocks = <0x4 0x83>;
		assigned-clock-parents = <0x4 0x1b>;
		assigned-clock-rates = <0x1770000>;
		phandle = <0x64>;
	};

	sai@308b0000 {
		compatible = "fsl,imx8mq-sai", "fsl,imx6sx-sai";
		reg = <0x0 0x308b0000 0x0 0x10000>;
		interrupts = <0x0 0x60 0x4>;
		clocks = <0x4 0xfd 0x4 0x0 0x4 0xd3 0x4 0x0 0x4 0x0>;
		clock-names = "bus", "mclk0", "mclk1", "mclk2", "mclk3";
		dmas = <0x2b 0xa 0x18 0x0 0x2b 0xb 0x18 0x0>;
		dma-names = "rx", "tx";
		status = "okay";
		pinctrl-names = "default";
		pinctrl-0 = <0x3d>;
		assigned-clocks = <0x4 0x81>;
		assigned-clock-parents = <0x4 0x1b>;
		assigned-clock-rates = <0x1770000>;
		phandle = <0x62>;
	};

	sai@308c0000 {
		compatible = "fsl,imx8mq-sai", "fsl,imx6sx-sai";
		reg = <0x0 0x308c0000 0x0 0x10000>;
		interrupts = <0x0 0x32 0x4>;
		clocks = <0x4 0xfe 0x4 0x0 0x4 0xd4 0x4 0x0 0x4 0x0>;
		clock-names = "bus", "mclk0", "mclk1", "mclk2", "mclk3";
		dmas = <0x2b 0xc 0x18 0x0 0x2b 0xd 0x18 0x0>;
		dma-names = "rx", "tx";
		status = "disabled";
	};

	sdma@30bd0000 {
		compatible = "fsl,imx8mq-sdma", "fsl,imx7d-sdma";
		reg = <0x0 0x30bd0000 0x0 0x10000>;
		interrupts = <0x0 0x2 0x4>;
		clocks = <0x4 0xf1 0x4 0xf1>;
		clock-names = "ipg", "ahb";
		#dma-cells = <0x3>;
		fsl,sdma-ram-script-name = "imx/sdma/sdma-imx7d.bin";
		status = "okay";
		phandle = <0x2b>;
	};

	sdma@302c0000 {
		compatible = "fsl,imx8mq-sdma", "fsl,imx7d-sdma";
		reg = <0x0 0x302c0000 0x0 0x10000>;
		interrupts = <0x0 0x67 0x4>;
		clocks = <0x4 0xf2 0x4 0xf2>;
		clock-names = "ipg", "ahb";
		#dma-cells = <0x3>;
		fsl,sdma-ram-script-name = "imx/sdma/sdma-imx7d.bin";
		fsl,ratio-1-1;
		status = "okay";
		phandle = <0x38>;
	};

	ethernet@30be0000 {
		compatible = "fsl,imx8mq-fec", "fsl,imx6sx-fec";
		reg = <0x0 0x30be0000 0x0 0x10000>;
		interrupts = <0x0 0x76 0x4 0x0 0x77 0x4 0x0 0x78 0x4>;
		clocks = <0x4 0xc4 0x4 0xc4 0x4 0x89 0x4 0x88 0x4 0x8a>;
		clock-names = "ipg", "ahb", "ptp", "enet_clk_ref", "enet_out";
		assigned-clocks = <0x4 0x68 0x4 0x89 0x4 0x88 0x4 0x89>;
		assigned-clock-parents = <0x4 0x4c 0x4 0x50 0x4 0x51>;
		assigned-clock-rates = <0x0 0x0 0x7735940 0x5f5e100>;
		stop-mode = <0x13 0x10 0x3>;
		fsl,num-tx-queues = <0x3>;
		fsl,num-rx-queues = <0x3>;
		fsl,wakeup_irq = <0x2>;
		status = "okay";
		pinctrl-names = "default";
		pinctrl-0 = <0x3e>;
		phy-mode = "rgmii-id";
		phy-handle = <0x3f>;
		fsl,magic-packet;

		mdio {
			#address-cells = <0x1>;
			#size-cells = <0x0>;

			ethernet-phy@0 {
				compatible = "ethernet-phy-ieee802.3-c22";
				reg = <0x0>;
				at803x,led-act-blind-workaround;
				at803x,eee-disabled;
				phandle = <0x3f>;
			};
		};
	};

	gpu@38000000 {
		compatible = "fsl,imx8mq-gpu", "fsl,imx6q-gpu";
		/* reg = <0x0 0x38000000 0x0 0x40000 0x0 0x40000000 0x0 0xc0000000 0x0 0x0
		 * 0x0 0x10000000>; */
		reg = <0x0 0x38000000 0x0 0x40000 0x0 0x50000000 0x0 0xb0000000 0x0 0x0 0x0 0x10000000>;
		reg-names = "iobase_3d", "phys_baseaddr", "contiguous_mem";
		interrupts = <0x0 0x3 0x4>;
		interrupt-names = "irq_3d";
		clocks = <0x4 0xe5 0x4 0x66 0x4 0x6f 0x4 0x70>;
		clock-names = "gpu3d_clk", "gpu3d_shader_clk", "gpu3d_axi_clk", "gpu3d_ahb_clk";
		assigned-clocks = <0x4 0x61 0x4 0x64 0x4 0x6f 0x4 0x70>;
		assigned-clock-parents = <0x4 0x11 0x4 0x11 0x4 0x11 0x4 0x11>;
		assigned-clock-rates = <0x2faf0800 0x2faf0800 0x2faf0800 0x2faf0800>;
		power-domains = <0x40>;
		status = "okay";
		gpu-noc-priority = <0x80000600>;
	};

	imx_ion {
		compatible = "fsl,mxc-ion";
		fsl,heap-id = <0x0>;
	};

	i2c@30a20000 {
		#address-cells = <0x1>;
		#size-cells = <0x0>;
		compatible = "fsl,imx21-i2c";
		reg = <0x0 0x30a20000 0x0 0x10000>;
		interrupts = <0x0 0x23 0x4>;
		clocks = <0x4 0xc6>;
		status = "okay";
		clock-frequency = <0x61a80>;
		pinctrl-names = "default";
		pinctrl-0 = <0x41>;

		pfuze100@8 {
			compatible = "fsl,pfuze100";
			reg = <0x8>;

			regulators {

				sw1ab {
					regulator-min-microvolt = <0x493e0>;
					regulator-max-microvolt = <0x1c9c38>;
					phandle = <0xb>;
				};

				sw1c {
					regulator-min-microvolt = <0x493e0>;
					regulator-max-microvolt = <0x1c9c38>;
					phandle = <0xc>;
				};

				sw2 {
					regulator-min-microvolt = <0xc3500>;
					regulator-max-microvolt = <0x325aa0>;
					regulator-always-on;
				};

				sw3ab {
					regulator-min-microvolt = <0x61a80>;
					regulator-max-microvolt = <0x1e22d8>;
					regulator-always-on;
				};

				sw4 {
					regulator-min-microvolt = <0xc3500>;
					regulator-max-microvolt = <0x325aa0>;
					regulator-always-on;
				};

				swbst {
					regulator-min-microvolt = <0x4c4b40>;
					regulator-max-microvolt = <0x4e9530>;
				};

				vsnvs {
					regulator-min-microvolt = <0xf4240>;
					regulator-max-microvolt = <0x2dc6c0>;
					regulator-always-on;
				};

				vrefddr {
					regulator-always-on;
				};

				vgen1 {
					regulator-min-microvolt = <0xc3500>;
					regulator-max-microvolt = <0x17a6b0>;
				};

				vgen2 {
					regulator-min-microvolt = <0xc3500>;
					regulator-max-microvolt = <0x17a6b0>;
					regulator-always-on;
				};

				vgen3 {
					regulator-min-microvolt = <0x1b7740>;
					regulator-max-microvolt = <0x325aa0>;
					regulator-always-on;
				};

				vgen4 {
					regulator-min-microvolt = <0x1b7740>;
					regulator-max-microvolt = <0x325aa0>;
					regulator-always-on;
				};

				vgen5 {
					regulator-min-microvolt = <0x1b7740>;
					regulator-max-microvolt = <0x325aa0>;
					regulator-always-on;
				};

				vgen6 {
					regulator-min-microvolt = <0x1b7740>;
					regulator-max-microvolt = <0x325aa0>;
				};
			};
		};

		ptn5110@50 {
			compatible = "nxp,ptn5110";
			pinctrl-names = "default";
			pinctrl-0 = <0x42>;
			reg = <0x50>;
			interrupt-parent = <0x43>;
			interrupts = <0x3 0x8>;
			ss-sel-gpios = <0x43 0xf 0x0>;
			phandle = <0x5a>;

			connector {
				compatible = "usb-c-connector";
				label = "USB-C";
				power-role = "dual";
				data-role = "dual";
				try-power-role = "sink";
				source-pdos = <0x401912c>;
				sink-pdos = <0x401912c 0x9901912c>;
				op-sink-microwatt = <0xe4e1c0>;
				self-powered;
			};
		};

		ov5640_mipi2@3c {
			compatible = "ovti,ov5640_mipi";
			reg = <0x3c>;
			status = "okay";
			pinctrl-names = "default";
			pinctrl-0 = <0x44 0x45>;
			clocks = <0x4 0x115>;
			clock-names = "csi_mclk";
			assigned-clocks = <0x4 0x115>;
			assigned-clock-parents = <0x4 0x53>;
			assigned-clock-rates = <0x1312d00>;
			csi_id = <0x1>;
			pwn-gpios = <0x46 0x5 0x0>;
			mclk = <0x1312d00>;
			mclk_source = <0x0>;

			port {

				endpoint {
					remote-endpoint = <0x47>;
					phandle = <0x17>;
				};
			};
		};
	};

	i2c@30a30000 {
		#address-cells = <0x1>;
		#size-cells = <0x0>;
		compatible = "fsl,imx21-i2c";
		reg = <0x0 0x30a30000 0x0 0x10000>;
		interrupts = <0x0 0x24 0x4>;
		clocks = <0x4 0xc7>;
		status = "okay";
		clock-frequency = <0x186a0>;
		pinctrl-names = "default";
		pinctrl-0 = <0x48>;

		ov5640_mipi@3c {
			compatible = "ovti,ov5640_mipi";
			reg = <0x3c>;
			status = "okay";
			pinctrl-names = "default";
			pinctrl-0 = <0x49>;
			clocks = <0x4 0x115>;
			clock-names = "csi_mclk";
			assigned-clocks = <0x4 0x115>;
			assigned-clock-parents = <0x4 0x53>;
			assigned-clock-rates = <0x1312d00>;
			csi_id = <0x0>;
			pwn-gpios = <0x46 0x3 0x0>;
			mclk = <0x1312d00>;
			mclk_source = <0x0>;

			port {

				endpoint {
					remote-endpoint = <0x4a>;
					phandle = <0x14>;
				};
			};
		};
	};

	i2c@30a40000 {
		#address-cells = <0x1>;
		#size-cells = <0x0>;
		compatible = "fsl,imx21-i2c";
		reg = <0x0 0x30a40000 0x0 0x10000>;
		interrupts = <0x0 0x25 0x4>;
		clocks = <0x4 0xc8>;
		status = "okay";
		clock-frequency = <0x186a0>;
		pinctrl-names = "default";
		pinctrl-0 = <0x4b>;

		ak4458@10 {
			compatible = "asahi-kasei,ak4458";
			reg = <0x10>;
			phandle = <0x68>;
		};

		ak4458@12 {
			compatible = "asahi-kasei,ak4458";
			reg = <0x12>;
			phandle = <0x69>;
		};

		ak5558@13 {
			compatible = "asahi-kasei,ak5558";
			reg = <0x13>;
			ak5558,pdn-gpio = <0x43 0x11 0x0>;
			phandle = <0x6b>;
		};

		ak4497@11 {
			compatible = "asahi-kasei,ak4497";
			reg = <0x11>;
			ak4497,pdn-gpio = <0x43 0x10 0x0>;
			phandle = <0x6c>;
		};

		synaptics_dsx_ts@20 {
			compatible = "synaptics_dsx";
			reg = <0x20>;
			pinctrl-names = "default";
			pinctrl-0 = <0x4c>;
			interrupt-parent = <0x4d>;
			interrupts = <0x7 0x8>;
			synaptics,diagonal-rotation;
			status = "disabled";
		};

		adv7535@3d {
			compatible = "adi,adv7533";
			reg = <0x3d>;
			adi,addr-cec = <0x3b>;
			adi,dsi-lanes = <0x4>;
			pinctrl-0 = <0x4c>;
			interrupt-parent = <0x4d>;
			interrupts = <0x7 0x8>;
			status = "disabled";

			port {

				endpoint {
					remote-endpoint = <0x4e>;
					phandle = <0x1f>;
				};
			};
		};
	};

	i2c@30a50000 {
		#address-cells = <0x1>;
		#size-cells = <0x0>;
		compatible = "fsl,imx21-i2c";
		reg = <0x0 0x30a50000 0x0 0x10000>;
		interrupts = <0x0 0x26 0x4>;
		clocks = <0x4 0xc9>;
		status = "disabled";
	};

	vpu@38300000 {
		compatible = "nxp,imx8mq-hantro";
		reg = <0x0 0x38300000 0x0 0x200000>;
		reg-names = "regs_hantro";
		interrupts = <0x0 0x7 0x4 0x0 0x8 0x4>;
		interrupt-names = "irq_hantro_g1", "irq_hantro_g2";
		clocks = <0x4 0xf3 0x4 0xf4 0x4 0xed>;
		clock-names = "clk_hantro_g1", "clk_hantro_g2", "clk_hantro_bus";
		assigned-clocks = <0x4 0x77 0x4 0x78 0x4 0x6a>;
		assigned-clock-parents = <0x4 0x16 0x4 0x16 0x4 0x4e>;
		assigned-clock-rates = <0x23c34600 0x23c34600 0x2faf0800>;
		power-domains = <0x4f>;
		regulator-supply = <0xc>;
		status = "okay";
	};

	wdog@30280000 {
		compatible = "fsl,imx21-wdt";
		reg = <0x0 0x30280000 0x0 0x10000>;
		interrupts = <0x0 0x4e 0x4>;
		clocks = <0x4 0xe2>;
		status = "okay";
		pinctrl-names = "default";
		pinctrl-0 = <0x50>;
		fsl,ext-reset-output;
	};

	wdog@30290000 {
		compatible = "fsl,imx21-wdt";
		reg = <0x0 0x30290000 0x0 0x10000>;
		interrupts = <0x0 0x4f 0x4>;
		clocks = <0x4 0xe3>;
		status = "disabled";
	};

	wdog@302a0000 {
		compatible = "fsl,imx21-wdt";
		reg = <0x0 0x302a0000 0x0 0x10000>;
		interrupts = <0x0 0xa 0x4>;
		clocks = <0x4 0xe4>;
		status = "disabled";
	};

	dma_cap {
		compatible = "dma-capability";
		only-dma-mask32 = <0x1>;
	};

	qspi@30bb0000 {
		#address-cells = <0x1>;
		#size-cells = <0x0>;
		compatible = "fsl,imx7d-qspi";
		reg = <0x0 0x30bb0000 0x0 0x10000 0x0 0x8000000 0x0 0x10000000>;
		reg-names = "QuadSPI", "QuadSPI-memory";
		interrupts = <0x0 0x6b 0x4>;
		clocks = <0x4 0xd1 0x4 0xd1>;
		clock-names = "qspi_en", "qspi";
		status = "okay";
		pinctrl-names = "default";
		pinctrl-0 = <0x51>;

		n25q256a@0 {
			reg = <0x0>;
			#address-cells = <0x1>;
			#size-cells = <0x1>;
			compatible = "micron,n25q256a";
			spi-max-frequency = <0x1ba8140>;
			spi-nor,ddr-quad-read-dummy = <0x6>;
		};
	};
/*
	hsio {
		compatible = "simple-bus";
		#address-cells = <0x2>;
		#size-cells = <0x2>;
		ranges;
		dma-ranges = <0x0 0x40000000 0x0 0x40000000 0x0 0xc0000000>;

		pcie@33800000 {
			compatible = "fsl,imx8mq-pcie", "snps,dw-pcie";
			reg = <0x0 0x33800000 0x0 0x400000 0x0 0x1ff00000 0x0 0x80000>;
			reg-names = "dbi", "config";
			reserved-region = <0x52>;
			#address-cells = <0x3>;
			#size-cells = <0x2>;
			device_type = "pci";
			ranges = <0x81000000 0x0 0x0 0x0 0x1ff80000 0x0 0x10000 0x82000000 0x0 0x18000000 0x0 0x18000000 0x0 0x7f00000>;
			num-lanes = <0x1>;
			interrupts = <0x0 0x7a 0x4 0x0 0x7f 0x4>;
			interrupt-names = "msi";
			#interrupt-cells = <0x1>;
			interrupt-map-mask = <0x0 0x0 0x0 0x7>;
			interrupt-map = <0x0 0x0 0x0 0x1 0xa 0x0 0x7d 0x4 0x0 0x0 0x0 0x2 0xa 0x0 0x7c 0x4 0x0 0x0 0x0 0x3 0xa 0x0 0x7b 0x4 0x0 0x0 0x0 0x4 0xa 0x0 0x7a 0x4>;
			clocks = <0x4 0xcb 0x4 0x7d 0x4 0x7c>;
			clock-names = "pcie", "pcie_bus", "pcie_phy";
			fsl,max-link-speed = <0x2>;
			ctrl-id = <0x0>;
			power-domains = <0x53>;
			status = "okay";
			pinctrl-names = "default";
			pinctrl-0 = <0x54>;
			disable-gpio = <0x4d 0x1d 0x1>;
			reset-gpio = <0x4d 0x1c 0x1>;
			ext_osc = <0x1>;
			hard-wired = <0x1>;
		};

		pcie@33c00000 {
			compatible = "fsl,imx8mq-pcie", "snps,dw-pcie";
			reg = <0x0 0x33c00000 0x0 0x400000 0x0 0x27f00000 0x0 0x80000>;
			reg-names = "dbi", "config";
			reserved-region = <0x52>;
			#address-cells = <0x3>;
			#size-cells = <0x2>;
			device_type = "pci";
			ranges = <0x81000000 0x0 0x0 0x0 0x27f80000 0x0 0x10000 0x82000000 0x0 0x20000000 0x0 0x20000000 0x0 0x7f00000>;
			num-lanes = <0x1>;
			interrupts = <0x0 0x4a 0x4 0x0 0x50 0x4>;
			interrupt-names = "msi";
			#interrupt-cells = <0x1>;
			interrupt-map-mask = <0x0 0x0 0x0 0x7>;
			interrupt-map = <0x0 0x0 0x0 0x1 0xa 0x0 0x4d 0x4 0x0 0x0 0x0 0x2 0xa 0x0 0x4c 0x4 0x0 0x0 0x0 0x3 0xa 0x0 0x4b 0x4 0x0 0x0 0x0 0x4 0xa 0x0 0x4a 0x4>;
			clocks = <0x4 0xcc 0x4 0xaf 0x4 0xae>;
			clock-names = "pcie", "pcie_bus", "pcie_phy";
			fsl,max-link-speed = <0x2>;
			ctrl-id = <0x1>;
			power-domains = <0x55>;
			status = "okay";
			pinctrl-names = "default";
			pinctrl-0 = <0x56>;
			disable-gpio = <0x4d 0xa 0x1>;
			reset-gpio = <0x4d 0xc 0x1>;
			ext_osc = <0x1>;
		};
	};
*/
	ddr_pmu@3d800000 {
		compatible = "fsl,imx8-ddr-pmu";
		reg = <0x0 0x3d800000 0x0 0x400000>;
		interrupts = <0x0 0x62 0x4>;
	};

	imx_rpmsg {
		compatible = "fsl,rpmsg-bus", "simple-bus";
		#address-cells = <0x2>;
		#size-cells = <0x2>;
		ranges;

		rpmsg {
			compatible = "fsl,imx8mq-rpmsg";
			status = "disabled";
		};
	};

	caam@30900000 {
		compatible = "fsl,sec-v4.0";
		#address-cells = <0x1>;
		#size-cells = <0x1>;
		reg = <0x0 0x30900000 0x0 0x40000>;
		ranges = <0x0 0x0 0x30900000 0x40000>;
		interrupts = <0x0 0x5b 0x4>;
		status = "disabled";

		jr0@1000 {
			compatible = "fsl,sec-v4.0-job-ring";
			reg = <0x1000 0x1000>;
			interrupts = <0x0 0x69 0x4>;
		};

		jr1@2000 {
			compatible = "fsl,sec-v4.0-job-ring";
			reg = <0x2000 0x1000>;
			interrupts = <0x0 0x6a 0x4>;
		};

		jr2@3000 {
			compatible = "fsl,sec-v4.0-job-ring";
			reg = <0x3000 0x1000>;
			interrupts = <0x0 0x72 0x4>;
		};
	};

	caam-sm@100000 {
		compatible = "fsl,imx6q-caam-sm";
		reg = <0x0 0x100000 0x0 0x8000>;
	};

	caam-snvs@30370000 {
		compatible = "fsl,imx6q-caam-snvs";
		reg = <0x0 0x30370000 0x0 0x10000>;
	};

	caam_secvio {
		compatible = "fsl,imx7d-caam-secvio", "fsl,imx6q-caam-secvio";
		interrupts = <0x0 0x14 0x4>;
		jtag-tamper = "disabled";
		watchdog-tamper = "enabled";
		internal-boot-tamper = "enabled";
		external-pin-tamper = "disabled";
	};

	dma-apbh@33000000 {
		compatible = "fsl,imx7d-dma-apbh", "fsl,imx28-dma-apbh";
		reg = <0x0 0x33000000 0x0 0x2000>;
		interrupts = <0x0 0xc 0x4 0x0 0xc 0x4 0x0 0xc 0x4 0x0 0xc 0x4>;
		interrupt-names = "gpmi0", "gpmi1", "gpmi2", "gpmi3";
		#dma-cells = <0x1>;
		dma-channels = <0x4>;
		clocks = <0x4 0x116>;
		phandle = <0x57>;
	};

	gpmi-nand@33002000 {
		compatible = "fsl,imx7d-gpmi-nand";
		#address-cells = <0x1>;
		#size-cells = <0x1>;
		reg = <0x0 0x33002000 0x0 0x2000 0x0 0x33004000 0x0 0x4000>;
		reg-names = "gpmi-nand", "bch";
		interrupts = <0x0 0xe 0x4>;
		interrupt-names = "bch";
		clocks = <0x4 0xf0 0x4 0x116>;
		clock-names = "gpmi_io", "gpmi_bch_apb";
		dmas = <0x57 0x0>;
		dma-names = "rx-tx";
		status = "disabled";
	};

	usb@38100000 {
		compatible = "fsl,imx8mq-dwc3", "snps,dwc3";
		reg = <0x0 0x38100000 0x0 0x10000>;
		clocks = <0x4 0x6e 0x4 0xdc 0x4 0x1>;
		clock-names = "bus_early", "ref", "suspend";
		assigned-clocks = <0x4 0x6e 0x4 0x98>;
		assigned-clock-parents = <0x4 0x56 0x4 0x48>;
		assigned-clock-rates = <0x1dcd6500 0x5f5e100>;
		interrupts = <0x0 0x28 0x4>;
		phys = <0x58 0x58>;
		phy-names = "usb2-phy", "usb3-phy";
		power-domains = <0x59>;
		usb3-resume-missing-cas;
		usb3-lpm-capable;
		snps,has-lpm-erratum;
		snps,lpm-nyet-threshold = <0xf>;
		status = "okay";
		extcon = <0x5a>;
		dr_mode = "otg";
		hnp-disable;
		srp-disable;
		adp-disable;
	};

	usb-phy@381f0040 {
		compatible = "fsl,imx8mq-usb-phy";
		reg = <0x0 0x381f0040 0x0 0x40>;
		clocks = <0x4 0xde>;
		clock-names = "phy";
		assigned-clocks = <0x4 0x99>;
		assigned-clock-parents = <0x4 0x48>;
		assigned-clock-rates = <0x5f5e100>;
		#phy-cells = <0x0>;
		status = "okay";
		phandle = <0x58>;
	};

	usb@38200000 {
		compatible = "fsl,imx8mq-dwc3", "snps,dwc3";
		reg = <0x0 0x38200000 0x0 0x10000>;
		clocks = <0x4 0x6e 0x4 0xdd 0x4 0x1>;
		clock-names = "bus_early", "ref", "suspend";
		assigned-clocks = <0x4 0x6e 0x4 0x98>;
		assigned-clock-parents = <0x4 0x56 0x4 0x48>;
		assigned-clock-rates = <0x1dcd6500 0x5f5e100>;
		interrupts = <0x0 0x29 0x4>;
		phys = <0x5b 0x5b>;
		phy-names = "usb2-phy", "usb3-phy";
		power-domains = <0x5c>;
		usb3-resume-missing-cas;
		usb3-lpm-capable;
		status = "okay";
		dr_mode = "host";
	};

	usb-phy@382f0040 {
		compatible = "fsl,imx8mq-usb-phy";
		reg = <0x0 0x382f0040 0x0 0x40>;
		clocks = <0x4 0xdf>;
		clock-names = "phy";
		assigned-clocks = <0x4 0x99>;
		assigned-clock-parents = <0x4 0x48>;
		assigned-clock-rates = <0x5f5e100>;
		#phy-cells = <0x0>;
		status = "okay";
		phandle = <0x5b>;
	};

	firmware {

		android {
			compatible = "android,firmware";

			fstab {
				compatible = "android,fstab";

				system {
					compatible = "android,system";
					dev = "/dev/block/platform/30b40000.usdhc/by-name/system";
					dev_mmcblk1 = "/dev/block/platform/30b50000.usdhc/by-name/system";
					dev_mmcblk0 = "/dev/block/platform/30b40000.usdhc/by-name/system";
					type = "ext4";
					mnt_flags = "ro,barrier=1,inode_readahead_blks=8";
					fsmgr_flags = "wait,slotselect,avb,avb_keys=/avb/q-gsi.avbpubkey:/avb/r-gsi.avbpubkey:/avb/s-gsi.avbpubkey";
				};

				vendor {
					compatible = "android,vendor";
					dev = "/dev/block/platform/30b40000.usdhc/by-name/vendor";
					dev_mmcblk1 = "/dev/block/platform/30b50000.usdhc/by-name/vendor";
					dev_mmcblk0 = "/dev/block/platform/30b40000.usdhc/by-name/vendor";
					type = "ext4";
					mnt_flags = "ro,barrier=1,inode_readahead_blks=8";
					fsmgr_flags = "wait,slotselect,avb";
				};

				product {
					compatible = "android,product";
					dev = "/dev/block/platform/30b40000.usdhc/by-name/product";
					dev_mmcblk1 = "/dev/block/platform/30b50000.usdhc/by-name/product";
					dev_mmcblk0 = "/dev/block/platform/30b40000.usdhc/by-name/product";
					type = "ext4";
					mnt_flags = "ro,barrier=1,inode_readahead_blks=8";
					fsmgr_flags = "wait,slotselect,avb";
				};
			};

			vbmeta {
				compatible = "android,vbmeta";
				parts = "vbmeta,dtbo,boot,system,vendor,product";
			};
		};
	};

	trusty {
		compatible = "android,trusty-smc-v1";
		ranges;
		#address-cells = <0x2>;
		#size-cells = <0x2>;
		use-gicv3-workaround;

		trusty-irq {
			use-gicv3-workaround;
			compatible = "android,trusty-irq-v1";
			interrupt-templates = <0x5d 0x0>;
			interrupt-ranges = <0x0 0xf 0x0>;
		};

		trusty-virtio {
			compatible = "android,trusty-virtio-v1";
		};

		trusty-log {
			compatible = "android,trusty-log-v1";
		};
	};

	interrupt-controller@0 {
		compatible = "android,CustomIPI";
		interrupt-controller;
		#interrupt-cells = <0x1>;
		phandle = <0x5d>;
	};

	apb-pclk {
		compatible = "fixed-clock";
		phandle = <0x8000>;
		clock-output-names = "clk24mhz";
		clock-frequency = <0x16e3600>;
		#clock-cells = <0x00>;
	};

	pl011@9000000 {
		interrupts = <0x00 0x01 0x04>;
		compatible = "arm,pl011\0arm,primecell";
		clock-names = "uartclk\0apb_pclk";
		reg = <0x00 0x9000000 0x00 0x1000>;
		clocks = <0x8000 0x8000>;
	};

	chosen {
		/* bootargs = "root=/dev/block/dm-0 earlycon=pl011,0x9000000 init=/init cma=32M"; */
		bootargs = "androidboot.boot_device_root=mmcblk1 androidboot.hardware=freescale earlycon=pl011,0x9000000 clk_ignore_unused androidboot.console=pl011 init=/init cma=32M androidboot.slot_suffix=_a androidboot.force_normal_boot=1 rootwait androidboot.verifiedbootstate=orange androidboot.flash.locked=0 androidboot.vbmeta.device_state=unlocked androidboot.vbmeta.size=3904 androidboot.vbmeta.hash_alg=sha256 androidboot.vbmeta.digest=dee55885d7cc7139193417f989245dd3dcd738107ab114cc1148217eb9dbe280 androidboot.vbmeta.invalidate_on_error=no androidboot.veritymode=disabled  androidboot.vbmeta.device=PARTUUID=$(ANDROID_VBMETA_PARTUUID) androidboot.vbmeta.avb_version=1.1 androidboot.keystore=software _class.path=/vendor/firmware androidboot.gui_resolution=1080p androidboot.fbTileSupport=enable androidboot.primary_display=imx_drm transparent_hugepage=never androidboot.lcd_density=213 loop.max_part=7 androidboot.serialno=021961d6f32ef628 buildvariant=userdebug androidboot.soc_type=imx8mq";
		/* androidboot.slot_suffix=_a root=/dev/dm-0 dm='system none ro,0 1
		 * android-verity /dev/mmcblk1p5' rootwait skip_initramfs"; */
/*androidboot.gui_resolution=1080p androidboot.console=ttymxc0
 * androidboot.hardware=freescale androidboot.fbTileSupport=enable cma=1280M
 * androidboot.primary_display=imx-drm firmware _class.path=/vendor/firmware
 * transparent_hugepage=never loop.max_part=7 androidboot.lcd_density=213
 * androidboot.wificountrycode=CN buildvariant=user"; */
		linux,initrd-start = <0x53000000>;
		linux,initrd-end   = <0x536d9d6a>;
		stdout-path = "/pl011@9000000";
	};

	virtio_mmio@a000000 {
		interrupts = <0x00 0x10 0x01>;
		compatible = "virtio,mmio";
		dma-coherent;
		reg = <0x00 0xa000000 0x00 0x200>;
	};

	regulators {
		compatible = "simple-bus";
		#address-cells = <0x1>;
		#size-cells = <0x0>;

		usdhc2_vmmc {
			compatible = "regulator-fixed";
			regulator-name = "VSD_3V3";
			regulator-min-microvolt = <0x325aa0>;
			regulator-max-microvolt = <0x325aa0>;
			gpio = <0x36 0x13 0x0>;
			off-on-delay = <0x4e20>;
			enable-active-high;
			phandle = <0x37>;
		};

		regulator-gpio {
			compatible = "regulator-gpio";
			pinctrl-names = "default";
			pinctrl-0 = <0x5e>;
			regulator-min-microvolt = <0xdbba0>;
			regulator-max-microvolt = <0xf4240>;
			regulator-name = "gpio_dvfs";
			regulator-type = "voltage";
			gpios = <0x46 0xd 0x0>;
			states = <0xdbba0 0x1 0xf4240 0x0>;
			phandle = <0x5>;
		};
	};

	ir-receiver {
		compatible = "gpio-ir-receiver";
		gpios = <0x46 0xc 0x1>;
		pinctrl-names = "default";
		pinctrl-0 = <0x5f>;
	};

	brcmfmac {
		compatible = "cypress,brcmfmac";
		pinctrl-names = "init", "idle", "default";
		pinctrl-0 = <0x60>;
		pinctrl-1 = <0x60>;
		pinctrl-2 = <0x61>;
	};

	bt_rfkill {
		compatible = "fsl,mxc_bt_rfkill";
		bt-power-gpios = <0x43 0x5 0x1>;
		status = "okay";
	};

	wm8524 {
		compatible = "wlf,wm8524";
		clocks = <0x4 0xd3>;
		clock-names = "mclk";
		wlf,mute-gpios = <0x46 0x8 0x1>;
		phandle = <0x63>;
	};

	sound-wm8524 {
		compatible = "fsl,imx-audio-wm8524";
		model = "wm8524-audio";
		audio-cpu = <0x62>;
		audio-codec = <0x63>;
		audio-routing = "Line Out Jack", "LINEVOUTL", "Line Out Jack", "LINEVOUTR";
	};

	sound-hdmi {
		compatible = "fsl,imx8mq-evk-cdnhdmi", "fsl,imx-audio-cdnhdmi";
		model = "imx-audio-hdmi";
		audio-cpu = <0x64>;
		protocol = <0x1>;
		hdmi-out;
		constraint-rate = <0xac44 0x15888 0x2b110 0x7d00 0xbb80 0x17700 0x2ee00>;
	};

	sound-spdif {
		compatible = "fsl,imx-audio-spdif";
		model = "imx-spdif";
		spdif-controller = <0x65>;
		spdif-out;
		spdif-in;
	};

	sound-hdmi-arc {
		compatible = "fsl,imx-audio-spdif";
		model = "imx-hdmi-arc";
		spdif-controller = <0x66>;
		spdif-in;
	};

	sound-ak4458 {
		compatible = "fsl,imx-audio-ak4458-mq";
		model = "ak4458-audio";
		audio-cpu = <0x67>;
		audio-codec = <0x68 0x69>;
		ak4458,pdn-gpio = <0x43 0x12 0x0>;
	};

	sound-ak5558 {
		compatible = "fsl,imx-audio-ak5558-mq";
		model = "ak5558-audio";
		audio-cpu = <0x6a>;
		audio-codec = <0x6b>;
	};

	sound-ak4497 {
		compatible = "fsl,imx-audio-ak4497-mq";
		model = "ak4497-audio";
		audio-cpu = <0x67>;
		audio-codec = <0x6c>;
		status = "disabled";
	};
};
